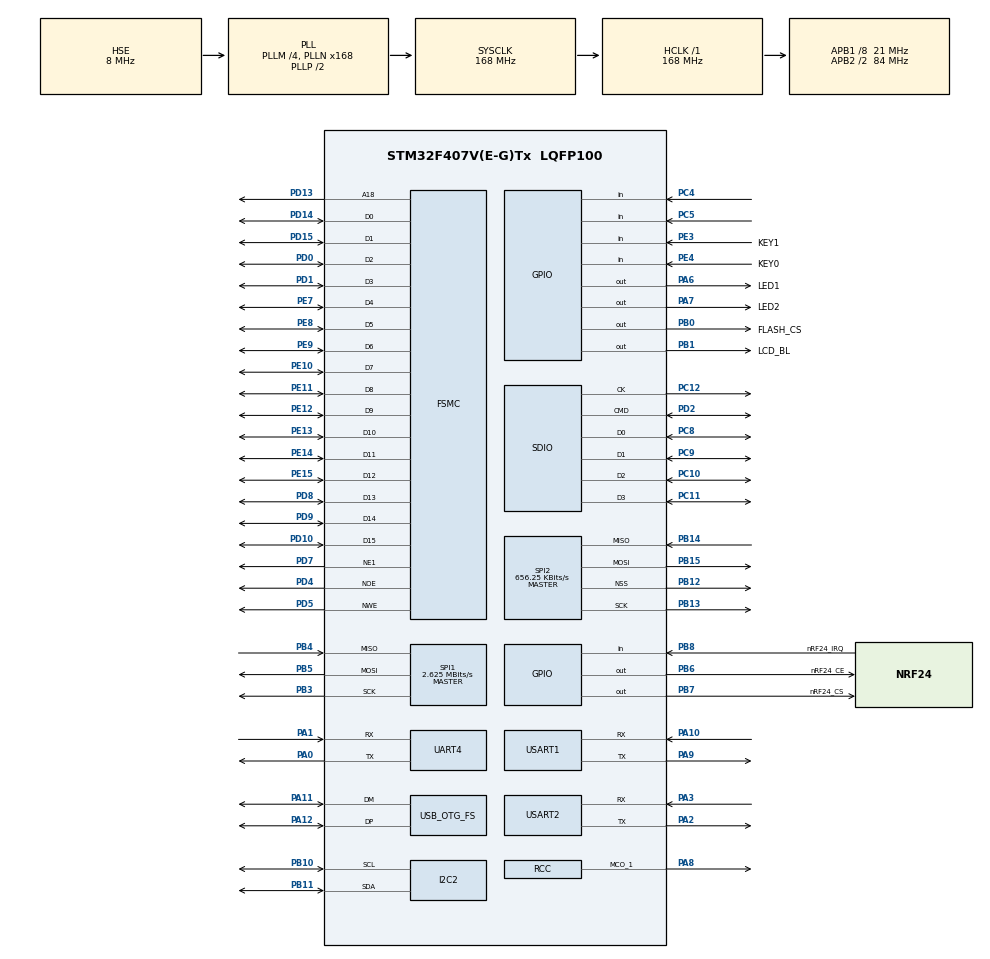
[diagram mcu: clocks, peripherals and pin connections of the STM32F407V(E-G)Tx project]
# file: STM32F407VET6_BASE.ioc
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Dma.Request0=USART1_TX
Dma.Request1=USART1_RX
Dma.USART1_RX.1.Direction=DMA_PERIPH_TO_MEMORY
Dma.USART1_RX.1.FIFOMode=DMA_FIFOMODE_DISABLE
Dma.USART1_RX.1.Instance=DMA2_Stream2
Dma.USART1_RX.1.MemDataAlignment=DMA_MDATAALIGN_BYTE
Dma.USART1_RX.1.MemInc=DMA_MINC_ENABLE
Dma.USART1_RX.1.Mode=DMA_NORMAL
Dma.USART1_RX.1.PeriphDataAlignment=DMA_PDATAALIGN_BYTE
Dma.USART1_RX.1.PeriphInc=DMA_PINC_DISABLE
Dma.USART1_RX.1.Priority=DMA_PRIORITY_MEDIUM
Dma.USART1_TX.0.Direction=DMA_MEMORY_TO_PERIPH
Dma.USART1_TX.0.FIFOMode=DMA_FIFOMODE_DISABLE
Dma.USART1_TX.0.Instance=DMA2_Stream7
Dma.USART1_TX.0.MemDataAlignment=DMA_MDATAALIGN_BYTE
Dma.USART1_TX.0.MemInc=DMA_MINC_ENABLE
Dma.USART1_TX.0.Mode=DMA_NORMAL
Dma.USART1_TX.0.PeriphDataAlignment=DMA_PDATAALIGN_BYTE
Dma.USART1_TX.0.PeriphInc=DMA_PINC_DISABLE
Dma.USART1_TX.0.Priority=DMA_PRIORITY_MEDIUM
FATFS.BSP.number=1
FATFS._MAX_SS=4096
FATFS0.BSP.STBoard=false
FATFS0.BSP.api=Unknown
FATFS0.BSP.i2caddr=0
FATFS0.BSP.instance=PC4
FATFS0.BSP.ip=GPIO
FATFS0.BSP.mode=Input
FATFS0.BSP.name=Detect_SDIO
FATFS0.BSP.solution=PC4
Mcu.Family=STM32F4
Mcu.Name=STM32F407V(E-G)Tx
Mcu.Package=LQFP100
NVIC.DMA2_Stream2_IRQn=true\:0\:0\:false\:false\:true\:false\:true
NVIC.DMA2_Stream7_IRQn=true\:0\:0\:false\:false\:true\:false\:true
NVIC.OTG_FS_IRQn=true\:0\:0\:false\:false\:true\:false\:true
NVIC.PriorityGroup=NVIC_PRIORITYGROUP_4
NVIC.TIM6_DAC_IRQn=true\:0\:0\:false\:false\:true\:true\:true
NVIC.USART1_IRQn=true\:0\:0\:false\:false\:true\:true\:true
PA0-WKUP.Mode=Asynchronous
PA0-WKUP.Signal=UART4_TX
PA1.Mode=Asynchronous
PA1.Signal=UART4_RX
PA10.Mode=Asynchronous
PA10.Signal=USART1_RX
PA11.Mode=Device_Only
PA11.Signal=USB_OTG_FS_DM
PA12.Mode=Device_Only
PA12.Signal=USB_OTG_FS_DP
PA2.Mode=Asynchronous
PA2.Signal=USART2_TX
PA3.Mode=Asynchronous
PA3.Signal=USART2_RX
PA6.GPIO_Label=LED1
PA6.Signal=GPIO_Output
PA7.GPIO_Label=LED2
PA7.Signal=GPIO_Output
PA8.Mode=Clock-out-1
PA8.Signal=RCC_MCO_1
PA9.Mode=Asynchronous
PA9.Signal=USART1_TX
PB0.GPIO_Label=FLASH_CS
PB0.Signal=GPIO_Output
PB1.GPIO_Label=LCD_BL
PB1.Signal=GPIO_Output
PB10.Mode=I2C
PB10.Signal=I2C2_SCL
PB11.Mode=I2C
PB11.Signal=I2C2_SDA
PB12.GPIO_PuPd=GPIO_NOPULL
PB12.Mode=NSS_Signal_Hard_Output
PB12.Signal=SPI2_NSS
PB13.Mode=Full_Duplex_Master
PB13.Signal=SPI2_SCK
PB14.Mode=Full_Duplex_Master
PB14.Signal=SPI2_MISO
PB15.Mode=Full_Duplex_Master
PB15.Signal=SPI2_MOSI
PB3.GPIO_Speed=GPIO_SPEED_FREQ_HIGH
PB3.Mode=Full_Duplex_Master
PB3.Signal=SPI1_SCK
PB4.GPIO_Speed=GPIO_SPEED_FREQ_HIGH
PB4.Mode=Full_Duplex_Master
PB4.Signal=SPI1_MISO
PB5.GPIO_Speed=GPIO_SPEED_FREQ_HIGH
PB5.Mode=Full_Duplex_Master
PB5.Signal=SPI1_MOSI
PB6.GPIO_Label=nRF24_CE
PB6.Signal=GPIO_Output
PB7.GPIO_Label=nRF24_CS
PB7.Signal=GPIO_Output
PB8.GPIO_Label=nRF24_IRQ
PB8.Signal=GPIO_Input
PC10.GPIO_PuPd=GPIO_PULLUP
PC10.Mode=SD_4_bits_Wide_bus
PC10.Signal=SDIO_D2
PC11.GPIO_PuPd=GPIO_PULLUP
PC11.Mode=SD_4_bits_Wide_bus
PC11.Signal=SDIO_D3
PC12.Mode=SD_4_bits_Wide_bus
PC12.Signal=SDIO_CK
PC14-OSC32_IN.Mode=LSE-External-Oscillator
PC14-OSC32_IN.Signal=RCC_OSC32_IN
PC15-OSC32_OUT.Mode=LSE-External-Oscillator
PC15-OSC32_OUT.Signal=RCC_OSC32_OUT
PC4.Signal=GPIO_Input
PC5.Signal=GPIO_Input
PC8.GPIO_PuPd=GPIO_PULLUP
PC8.Mode=SD_4_bits_Wide_bus
PC8.Signal=SDIO_D0
PC9.GPIO_PuPd=GPIO_PULLUP
PC9.Mode=SD_4_bits_Wide_bus
PC9.Signal=SDIO_D1
PD0.GPIO_PuPd=GPIO_PULLDOWN
PD0.GPIO_Speed_High_Default=GPIO_SPEED_FREQ_MEDIUM
PD0.Mode=16b-d1
PD0.Signal=FSMC_D2
PD1.GPIO_PuPd=GPIO_PULLDOWN
PD1.GPIO_Speed_High_Default=GPIO_SPEED_FREQ_MEDIUM
PD1.Mode=16b-d1
PD1.Signal=FSMC_D3
PD10.GPIO_PuPd=GPIO_PULLDOWN
PD10.GPIO_Speed_High_Default=GPIO_SPEED_FREQ_MEDIUM
PD10.Mode=16b-d1
PD10.Signal=FSMC_D15
PD13.Mode=A18_1
PD13.Signal=FSMC_A18
PD14.GPIO_PuPd=GPIO_PULLDOWN
PD14.GPIO_Speed_High_Default=GPIO_SPEED_FREQ_MEDIUM
PD14.Mode=16b-d1
PD14.Signal=FSMC_D0
PD15.GPIO_PuPd=GPIO_PULLDOWN
PD15.GPIO_Speed_High_Default=GPIO_SPEED_FREQ_MEDIUM
PD15.Mode=16b-d1
PD15.Signal=FSMC_D1
PD2.GPIO_PuPd=GPIO_PULLUP
PD2.Mode=SD_4_bits_Wide_bus
PD2.Signal=SDIO_CMD
PD4.GPIO_PuPd=GPIO_PULLDOWN
PD4.GPIO_Speed_High_Default=GPIO_SPEED_FREQ_MEDIUM
PD4.Mode=Lcd1
PD4.Signal=FSMC_NOE
PD5.GPIO_PuPd=GPIO_PULLDOWN
PD5.GPIO_Speed_High_Default=GPIO_SPEED_FREQ_MEDIUM
PD5.Mode=Lcd1
PD5.Signal=FSMC_NWE
PD7.GPIO_PuPd=GPIO_PULLDOWN
PD7.GPIO_Speed_High_Default=GPIO_SPEED_FREQ_MEDIUM
PD7.Mode=NorPsramChipSelect1_1
PD7.Signal=FSMC_NE1
PD8.GPIO_PuPd=GPIO_PULLDOWN
PD8.GPIO_Speed_High_Default=GPIO_SPEED_FREQ_MEDIUM
PD8.Mode=16b-d1
PD8.Signal=FSMC_D13
PD9.GPIO_PuPd=GPIO_PULLDOWN
PD9.GPIO_Speed_High_Default=GPIO_SPEED_FREQ_MEDIUM
PD9.Mode=16b-d1
PD9.Signal=FSMC_D14
PE10.GPIO_PuPd=GPIO_PULLDOWN
PE10.GPIO_Speed_High_Default=GPIO_SPEED_FREQ_MEDIUM
PE10.Mode=16b-d1
PE10.Signal=FSMC_D7
PE11.GPIO_PuPd=GPIO_PULLDOWN
PE11.GPIO_Speed_High_Default=GPIO_SPEED_FREQ_MEDIUM
PE11.Mode=16b-d1
PE11.Signal=FSMC_D8
PE12.GPIO_PuPd=GPIO_PULLDOWN
PE12.GPIO_Speed_High_Default=GPIO_SPEED_FREQ_MEDIUM
PE12.Mode=16b-d1
PE12.Signal=FSMC_D9
PE13.GPIO_PuPd=GPIO_PULLDOWN
PE13.GPIO_Speed_High_Default=GPIO_SPEED_FREQ_MEDIUM
PE13.Mode=16b-d1
PE13.Signal=FSMC_D10
PE14.GPIO_PuPd=GPIO_PULLDOWN
PE14.GPIO_Speed_High_Default=GPIO_SPEED_FREQ_MEDIUM
PE14.Mode=16b-d1
PE14.Signal=FSMC_D11
PE15.GPIO_PuPd=GPIO_PULLDOWN
PE15.GPIO_Speed_High_Default=GPIO_SPEED_FREQ_MEDIUM
PE15.Mode=16b-d1
PE15.Signal=FSMC_D12
PE3.GPIO_Label=KEY1
PE3.Signal=GPIO_Input
PE4.GPIO_Label=KEY0
PE4.Signal=GPIO_Input
PE7.GPIO_PuPd=GPIO_PULLDOWN
PE7.GPIO_Speed_High_Default=GPIO_SPEED_FREQ_MEDIUM
PE7.Mode=16b-d1
PE7.Signal=FSMC_D4
PE8.GPIO_PuPd=GPIO_PULLDOWN
PE8.GPIO_Speed_High_Default=GPIO_SPEED_FREQ_MEDIUM
PE8.Mode=16b-d1
PE8.Signal=FSMC_D5
PE9.GPIO_PuPd=GPIO_PULLDOWN
PE9.GPIO_Speed_High_Default=GPIO_SPEED_FREQ_HIGH
PE9.Mode=16b-d1
PE9.Signal=FSMC_D6
PH0-OSC_IN.Mode=HSE-External-Oscillator
PH0-OSC_IN.Signal=RCC_OSC_IN
PH1-OSC_OUT.Mode=HSE-External-Oscillator
PH1-OSC_OUT.Signal=RCC_OSC_OUT
ProjectManager.HeapSize=0x400
ProjectManager.StackSize=0x400
ProjectManager.TargetToolchain=MDK-ARM V5
RCC.48MHZClocksFreq_Value=48000000
RCC.AHBFreq_Value=168000000
RCC.APB1CLKDivider=RCC_HCLK_DIV8
RCC.APB1Freq_Value=21000000
RCC.APB1TimFreq_Value=42000000
RCC.APB2CLKDivider=RCC_HCLK_DIV2
RCC.APB2Freq_Value=84000000
RCC.APB2TimFreq_Value=168000000
RCC.CortexFreq_Value=168000000
RCC.HCLKFreq_Value=168000000
RCC.HSE_VALUE=8000000
RCC.HSI_VALUE=16000000
RCC.PLLM=4
RCC.PLLN=168
RCC.PLLQ=7
RCC.SYSCLKFreq_VALUE=168000000
RCC.SYSCLKSource=RCC_SYSCLKSOURCE_PLLCLK
RCC.VCOOutputFreq_Value=336000000
RTC.Alarm=RTC_ALARM_A
SPI1.BaudRatePrescaler=SPI_BAUDRATEPRESCALER_32
SPI1.CalculateBaudRate=2.625 MBits/s
SPI1.Direction=SPI_DIRECTION_2LINES
SPI1.Mode=SPI_MODE_MASTER
SPI1.VirtualType=VM_MASTER
SPI2.BaudRatePrescaler=SPI_BAUDRATEPRESCALER_32
SPI2.CalculateBaudRate=656.25 KBits/s
SPI2.Direction=SPI_DIRECTION_2LINES
SPI2.Mode=SPI_MODE_MASTER
SPI2.VirtualNSS=VM_NSSHARD
SPI2.VirtualType=VM_MASTER
TIM6.Period=499
TIM6.Prescaler=20999
TIM6.TIM_MasterOutputTrigger=TIM_TRGO_UPDATE
UART4.VirtualMode=Asynchronous
USART1.VirtualMode=VM_ASYNC
USART2.VirtualMode=VM_ASYNC
USB_DEVICE.CLASS_NAME_FS=CDC
USB_DEVICE.VirtualMode-CDC_FS=Cdc
USB_DEVICE.VirtualModeFS=Cdc_FS
USB_OTG_FS.VirtualMode=Device_Only
VP_FATFS_VS_SDIO.Mode=SDIO
VP_RTC_VS_RTC_Activate.Mode=RTC_Enabled
VP_RTC_VS_RTC_Alarm_A_Intern.Mode=Alarm A
VP_RTC_VS_RTC_Calendar.Mode=RTC_Calendar
VP_TIM6_VS_ClockSourceINT.Mode=Enable_Timer
VP_USB_DEVICE_VS_USB_DEVICE_CDC_FS.Mode=CDC_FS
board=custom

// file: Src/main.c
/* USER CODE BEGIN Header */
/**
  ******************************************************************************
  * @file           : main.c
  * @brief          : Main program body
  ******************************************************************************
  * @attention
  *
  * <h2><center>&copy; Copyright (c) 2019 STMicroelectronics.
  * All rights reserved.</center></h2>
  *
  * This software component is licensed by ST under Ultimate Liberty license
  * SLA0044, the "License"; You may not use this file except in compliance with
  * the License. You may obtain a copy of the License at:
  *                             www.st.com/SLA0044
  *
  ******************************************************************************
  */
/* USER CODE END Header */

#include "main.h"
#include "dma.h"
#include "fatfs.h"
#include "i2c.h"
#include "rtc.h"
#include "sdio.h"
#include "spi.h"
#include "tim.h"
#include "usart.h"
#include "usb_device.h"
#include "gpio.h"
#include "fsmc.h"

/* USER CODE BEGIN Includes */
#include "usbd_cdc_if.h"  // ����������  ������� ������ � �������� �� USB
#include <string.h>
#include "User_usart.h"

/* USER CODE END Includes */

void SystemClock_Config(void);

int main(void)
{
  /* USER CODE BEGIN 1 */
   char str_tx[21];
  /* USER CODE END 1 */

  /* MCU Configuration--------------------------------------------------------*/

  /* Reset of all peripherals, Initializes the Flash interface and the Systick. */
  HAL_Init();

  /* Configure the system clock */
  SystemClock_Config();

  /* Initialize all configured peripherals */
  MX_GPIO_Init();
  MX_DMA_Init();
  MX_FSMC_Init();
  MX_SDIO_SD_Init();
  MX_SPI2_Init();
  MX_FATFS_Init();
  MX_USB_DEVICE_Init();
  MX_USART1_UART_Init();
  MX_SPI1_Init();
  MX_RTC_Init();
  MX_TIM6_Init();
  MX_I2C2_Init();
  MX_UART4_Init();
  MX_USART2_UART_Init();
  /* USER CODE BEGIN 2 */

    HAL_TIM_Base_Start(&htim6);       // ��������� ������ TIM6
    HAL_TIM_Base_Start_IT(&htim6);    // ��������� ���������� �� ������� TIM6
//    int ledState = LOW;
//    unsigned long currentMillis = millis();
      // sprintf(str_tx,"USB Transmit\r\n");

  /* USER CODE END 2 */

  /* Infinite loop */
  /* USER CODE BEGIN WHILE */
  while (1)
  {
   // CDC_Transmit_FS((unsigned char*)str_tx, strlen(str_tx));
  printf("RTC was now initialized\r\n");
    HAL_Delay(300);

    /* USER CODE END WHILE */

  }
}

void SystemClock_Config(void)
{
  RCC_OscInitTypeDef RCC_OscInitStruct = {0};
  RCC_ClkInitTypeDef RCC_ClkInitStruct = {0};
  RCC_PeriphCLKInitTypeDef PeriphClkInitStruct = {0};

  /** Configure the main internal regulator output voltage
  */
  __HAL_RCC_PWR_CLK_ENABLE();
  __HAL_PWR_VOLTAGESCALING_CONFIG(PWR_REGULATOR_VOLTAGE_SCALE1);
  /** Initializes the CPU, AHB and APB busses clocks
  */
  RCC_OscInitStruct.OscillatorType = RCC_OSCILLATORTYPE_HSI|RCC_OSCILLATORTYPE_LSI
                              |RCC_OSCILLATORTYPE_HSE;
  RCC_OscInitStruct.HSEState = RCC_HSE_ON;
  RCC_OscInitStruct.HSIState = RCC_HSI_ON;
  RCC_OscInitStruct.HSICalibrationValue = RCC_HSICALIBRATION_DEFAULT;
  RCC_OscInitStruct.LSIState = RCC_LSI_ON;
  RCC_OscInitStruct.PLL.PLLState = RCC_PLL_ON;
  RCC_OscInitStruct.PLL.PLLSource = RCC_PLLSOURCE_HSE;
  RCC_OscInitStruct.PLL.PLLM = 4;
  RCC_OscInitStruct.PLL.PLLN = 168;
  RCC_OscInitStruct.PLL.PLLP = RCC_PLLP_DIV2;
  RCC_OscInitStruct.PLL.PLLQ = 7;
  if (HAL_RCC_OscConfig(&RCC_OscInitStruct) != HAL_OK)
  {
    Error_Handler();
  }
  /** Initializes the CPU, AHB and APB busses clocks
  */
  RCC_ClkInitStruct.ClockType = RCC_CLOCKTYPE_HCLK|RCC_CLOCKTYPE_SYSCLK
                              |RCC_CLOCKTYPE_PCLK1|RCC_CLOCKTYPE_PCLK2;
  RCC_ClkInitStruct.SYSCLKSource = RCC_SYSCLKSOURCE_PLLCLK;
  RCC_ClkInitStruct.AHBCLKDivider = RCC_SYSCLK_DIV1;
  RCC_ClkInitStruct.APB1CLKDivider = RCC_HCLK_DIV8;
  RCC_ClkInitStruct.APB2CLKDivider = RCC_HCLK_DIV2;

  if (HAL_RCC_ClockConfig(&RCC_ClkInitStruct, FLASH_LATENCY_5) != HAL_OK)
  {
    Error_Handler();
  }
  PeriphClkInitStruct.PeriphClockSelection = RCC_PERIPHCLK_RTC;
  PeriphClkInitStruct.RTCClockSelection = RCC_RTCCLKSOURCE_LSI;
  if (HAL_RCCEx_PeriphCLKConfig(&PeriphClkInitStruct) != HAL_OK)
  {
    Error_Handler();
  }
  HAL_RCC_MCOConfig(RCC_MCO1, RCC_MCO1SOURCE_HSI, RCC_MCODIV_1);
}

void Error_Handler(void)
{
}

/************************ (C) COPYRIGHT STMicroelectronics *****END OF FILE****/
